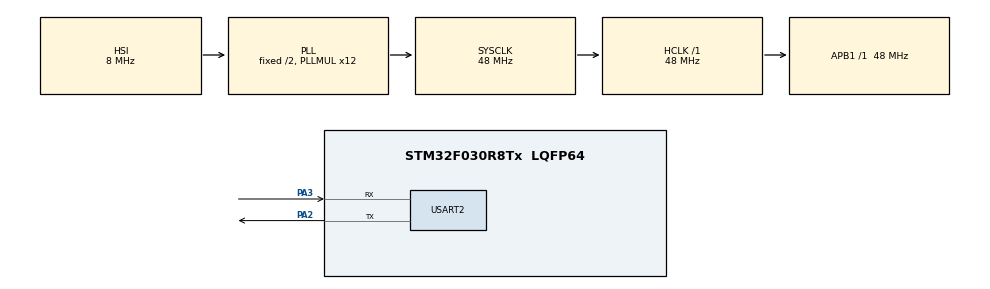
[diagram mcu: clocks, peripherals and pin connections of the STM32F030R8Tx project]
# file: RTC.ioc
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Mcu.Family=STM32F0
Mcu.Name=STM32F030R8Tx
Mcu.Package=LQFP64
PA13.Mode=Serial_Wire
PA13.Signal=SYS_SWDIO
PA14.Mode=Serial_Wire
PA14.Signal=SYS_SWCLK
PA2.Mode=Asynchronous
PA2.Signal=USART2_TX
PA3.Mode=Asynchronous
PA3.Signal=USART2_RX
ProjectManager.HeapSize=0x200
ProjectManager.StackSize=0x400
ProjectManager.TargetToolchain=STM32CubeIDE
RCC.AHBFreq_Value=48000000
RCC.APB1Freq_Value=48000000
RCC.APB1TimFreq_Value=48000000
RCC.HCLKFreq_Value=48000000
RCC.PLLMUL=RCC_PLL_MUL12
RCC.SYSCLKFreq_VALUE=48000000
RCC.SYSCLKSource=RCC_SYSCLKSOURCE_PLLCLK
RTC.Date=9
RTC.Hours=7
RTC.Minutes=40
RTC.Month=RTC_MONTH_MARCH
RTC.WeekDay=RTC_WEEKDAY_SUNDAY
RTC.Year=24
USART2.VirtualMode-Asynchronous=VM_ASYNC
VP_RTC_VS_RTC_Activate.Mode=RTC_Enabled
VP_RTC_VS_RTC_Calendar.Mode=RTC_Calendar
board=NUCLEO-F030R8

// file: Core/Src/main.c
/* USER CODE BEGIN Header */
/**
  ******************************************************************************
  * @file           : main.c
  * @brief          : Main program body
  ******************************************************************************
  * @attention
  *
  * Copyright (c) 2025 STMicroelectronics.
  * All rights reserved.
  *
  * This software is licensed under terms that can be found in the LICENSE file
  * in the root directory of this software component.
  * If no LICENSE file comes with this software, it is provided AS-IS.
  *
  ******************************************************************************
  */
/* USER CODE END Header */
#include "main.h"

/* USER CODE BEGIN Includes */
#include <stdio.h>

/* USER CODE END Includes */

RTC_HandleTypeDef hrtc;

UART_HandleTypeDef huart2;

/* USER CODE BEGIN PV */
char buffer[100]; // date and time string
/* USER CODE END PV */

void SystemClock_Config(void);
static void MX_GPIO_Init(void);
static void MX_USART2_UART_Init(void);
static void MX_RTC_Init(void);

/* USER CODE BEGIN 0 */
	// redirect output of fprint() to UART2
	int _write(int file, char *ptr, int len)
	{
		HAL_UART_Transmit(&huart2, (uint8_t *) ptr, len, HAL_MAX_DELAY);
		return len;
	}
/* USER CODE END 0 */

int main(void)
{

  /* MCU Configuration--------------------------------------------------------*/

  /* Reset of all peripherals, Initializes the Flash interface and the Systick. */
  HAL_Init();

  /* Configure the system clock */
  SystemClock_Config();

  /* Initialize all configured peripherals */
  MX_GPIO_Init();
  MX_USART2_UART_Init();
  MX_RTC_Init();
  /* USER CODE BEGIN 2 */
	RTC_TimeTypeDef sTime;
	RTC_DateTypeDef sDate;
	printf("\r\nSerial started at %d baud rate\r\n", huart2.Init.BaudRate);
  /* USER CODE END 2 */

  /* Infinite loop */
  while (1)
  {

    /* USER CODE BEGIN 3 */
	  // get tima and date
	  HAL_RTC_GetTime(&hrtc, &sTime, RTC_FORMAT_BIN);
	  HAL_RTC_GetDate(&hrtc, &sDate, RTC_FORMAT_BIN);

	  // send date and time to serial monitor
	  printf("Time is %02d:%02d:%02d, Date is %02d-%02d-%02d\r\n",
	  			  sTime.Hours, sTime.Minutes, sTime.Seconds,
	  			  sDate.Date, sDate.Month, sDate.Year + 2000);

	  HAL_Delay(1000);
  }
  /* USER CODE END 3 */
}

void SystemClock_Config(void)
{
  RCC_OscInitTypeDef RCC_OscInitStruct = {0};
  RCC_ClkInitTypeDef RCC_ClkInitStruct = {0};
  RCC_PeriphCLKInitTypeDef PeriphClkInit = {0};

  /** Initializes the RCC Oscillators according to the specified parameters
  * in the RCC_OscInitTypeDef structure.
  */
  RCC_OscInitStruct.OscillatorType = RCC_OSCILLATORTYPE_HSI|RCC_OSCILLATORTYPE_LSI;
  RCC_OscInitStruct.HSIState = RCC_HSI_ON;
  RCC_OscInitStruct.HSICalibrationValue = RCC_HSICALIBRATION_DEFAULT;
  RCC_OscInitStruct.LSIState = RCC_LSI_ON;
  RCC_OscInitStruct.PLL.PLLState = RCC_PLL_ON;
  RCC_OscInitStruct.PLL.PLLSource = RCC_PLLSOURCE_HSI;
  RCC_OscInitStruct.PLL.PLLMUL = RCC_PLL_MUL12;
  RCC_OscInitStruct.PLL.PREDIV = RCC_PREDIV_DIV1;
  if (HAL_RCC_OscConfig(&RCC_OscInitStruct) != HAL_OK)
  {
    Error_Handler();
  }

  /** Initializes the CPU, AHB and APB buses clocks
  */
  RCC_ClkInitStruct.ClockType = RCC_CLOCKTYPE_HCLK|RCC_CLOCKTYPE_SYSCLK
                              |RCC_CLOCKTYPE_PCLK1;
  RCC_ClkInitStruct.SYSCLKSource = RCC_SYSCLKSOURCE_PLLCLK;
  RCC_ClkInitStruct.AHBCLKDivider = RCC_SYSCLK_DIV1;
  RCC_ClkInitStruct.APB1CLKDivider = RCC_HCLK_DIV1;

  if (HAL_RCC_ClockConfig(&RCC_ClkInitStruct, FLASH_LATENCY_1) != HAL_OK)
  {
    Error_Handler();
  }
  PeriphClkInit.PeriphClockSelection = RCC_PERIPHCLK_RTC;
  PeriphClkInit.RTCClockSelection = RCC_RTCCLKSOURCE_LSI;
  if (HAL_RCCEx_PeriphCLKConfig(&PeriphClkInit) != HAL_OK)
  {
    Error_Handler();
  }
}

static void MX_RTC_Init(void)
{

  RTC_TimeTypeDef sTime = {0};
  RTC_DateTypeDef sDate = {0};

  /** Initialize RTC Only
  */
  hrtc.Instance = RTC;
  hrtc.Init.HourFormat = RTC_HOURFORMAT_24;
  hrtc.Init.AsynchPrediv = 127;
  hrtc.Init.SynchPrediv = 255;
  hrtc.Init.OutPut = RTC_OUTPUT_DISABLE;
  hrtc.Init.OutPutPolarity = RTC_OUTPUT_POLARITY_HIGH;
  hrtc.Init.OutPutType = RTC_OUTPUT_TYPE_OPENDRAIN;
  if (HAL_RTC_Init(&hrtc) != HAL_OK)
  {
    Error_Handler();
  }

  /** Initialize RTC and set the Time and Date
  */
  sTime.Hours = 0x7;
  sTime.Minutes = 0x40;
  sTime.Seconds = 0x0;
  sTime.DayLightSaving = RTC_DAYLIGHTSAVING_NONE;
  sTime.StoreOperation = RTC_STOREOPERATION_RESET;
  if (HAL_RTC_SetTime(&hrtc, &sTime, RTC_FORMAT_BCD) != HAL_OK)
  {
    Error_Handler();
  }
  sDate.WeekDay = RTC_WEEKDAY_SUNDAY;
  sDate.Month = RTC_MONTH_MARCH;
  sDate.Date = 0x9;
  sDate.Year = 0x24;

  if (HAL_RTC_SetDate(&hrtc, &sDate, RTC_FORMAT_BCD) != HAL_OK)
  {
    Error_Handler();
  }

}

static void MX_USART2_UART_Init(void)
{

  huart2.Instance = USART2;
  huart2.Init.BaudRate = 38400;
  huart2.Init.WordLength = UART_WORDLENGTH_8B;
  huart2.Init.StopBits = UART_STOPBITS_1;
  huart2.Init.Parity = UART_PARITY_NONE;
  huart2.Init.Mode = UART_MODE_TX_RX;
  huart2.Init.HwFlowCtl = UART_HWCONTROL_NONE;
  huart2.Init.OverSampling = UART_OVERSAMPLING_16;
  huart2.Init.OneBitSampling = UART_ONE_BIT_SAMPLE_DISABLE;
  huart2.AdvancedInit.AdvFeatureInit = UART_ADVFEATURE_NO_INIT;
  if (HAL_UART_Init(&huart2) != HAL_OK)
  {
    Error_Handler();
  }

}

static void MX_GPIO_Init(void)
{

  /* GPIO Ports Clock Enable */
  __HAL_RCC_GPIOA_CLK_ENABLE();

}

/* USER CODE BEGIN 4 */
//

/* USER CODE END 4 */

void Error_Handler(void)
{
  __disable_irq();
  while (1)
  {
  }
}
